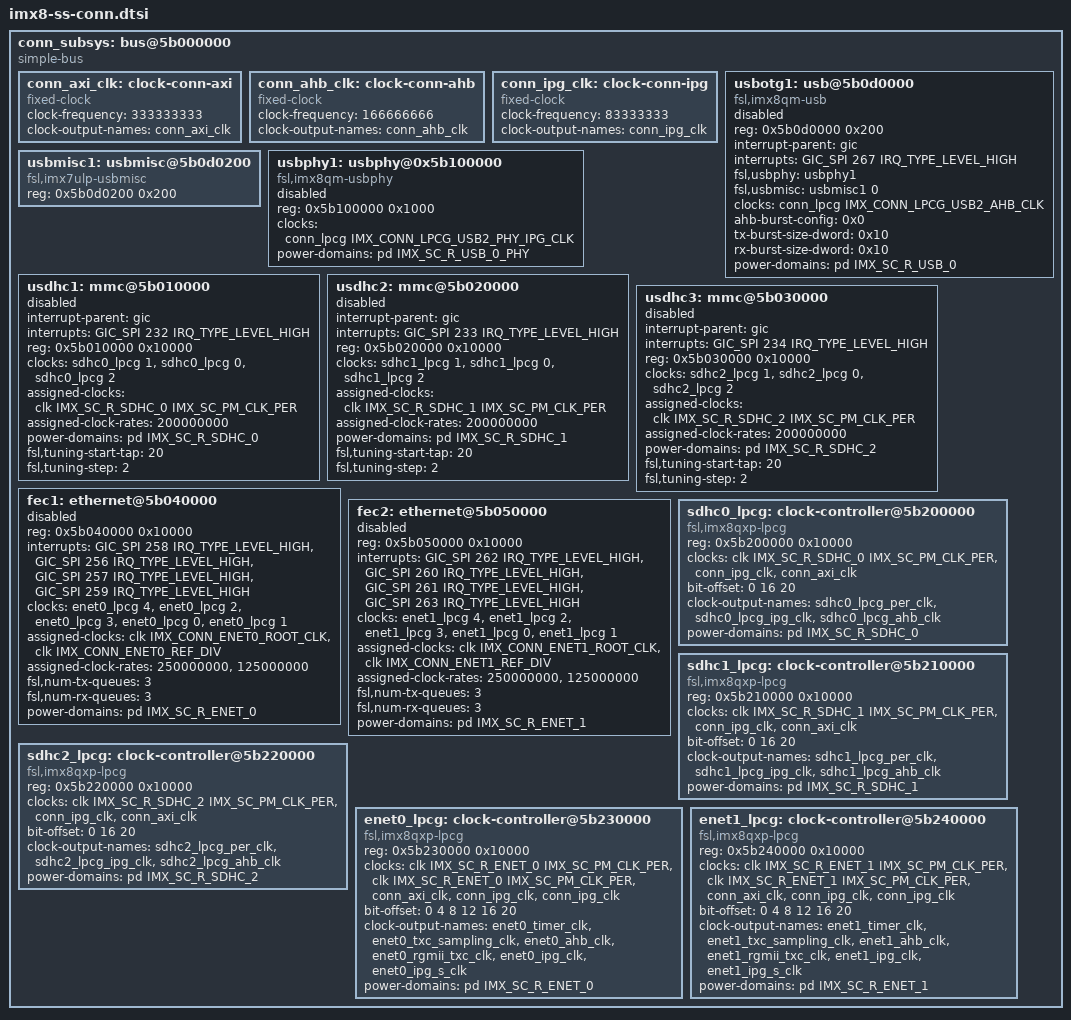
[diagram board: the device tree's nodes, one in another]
// SPDX-License-Identifier: GPL-2.0+
/*
 * Copyright 2018 NXP
 *	Dong Aisheng <aisheng.dong@nxp.com>
 */

#include <dt-bindings/firmware/imx/rsrc.h>

conn_subsys: bus@5b000000 {
	compatible = "simple-bus";
	#address-cells = <1>;
	#size-cells = <1>;
	ranges = <0x5b000000 0x0 0x5b000000 0x1000000>;

	conn_axi_clk: clock-conn-axi {
		compatible = "fixed-clock";
		#clock-cells = <0>;
		clock-frequency = <333333333>;
		clock-output-names = "conn_axi_clk";
	};

	conn_ahb_clk: clock-conn-ahb {
		compatible = "fixed-clock";
		#clock-cells = <0>;
		clock-frequency = <166666666>;
		clock-output-names = "conn_ahb_clk";
	};

	conn_ipg_clk: clock-conn-ipg {
		compatible = "fixed-clock";
		#clock-cells = <0>;
		clock-frequency = <83333333>;
		clock-output-names = "conn_ipg_clk";
	};

	usbotg1: usb@5b0d0000 {
		compatible = "fsl,imx8qm-usb", "fsl,imx7ulp-usb",
			"fsl,imx27-usb";
		reg = <0x5b0d0000 0x200>;
		interrupt-parent = <&gic>;
		interrupts = <GIC_SPI 267 IRQ_TYPE_LEVEL_HIGH>;
		fsl,usbphy = <&usbphy1>;
		fsl,usbmisc = <&usbmisc1 0>;
		clocks = <&conn_lpcg IMX_CONN_LPCG_USB2_AHB_CLK>;
		ahb-burst-config = <0x0>;
		tx-burst-size-dword = <0x10>;
		rx-burst-size-dword = <0x10>;
		power-domains = <&pd IMX_SC_R_USB_0>;
		status = "disabled";
	};

	usbmisc1: usbmisc@5b0d0200 {
		#index-cells = <1>;
		compatible = "fsl,imx7ulp-usbmisc", "fsl,imx6q-usbmisc";
		reg = <0x5b0d0200 0x200>;
	};

	usbphy1: usbphy@0x5b100000 {
		compatible = "fsl,imx8qm-usbphy", "fsl,imx7ulp-usbphy",
			"fsl,imx6ul-usbphy", "fsl,imx23-usbphy";
		reg = <0x5b100000 0x1000>;
		clocks = <&conn_lpcg IMX_CONN_LPCG_USB2_PHY_IPG_CLK>;
		power-domains = <&pd IMX_SC_R_USB_0_PHY>;
		status = "disabled";
	};

	usdhc1: mmc@5b010000 {
		interrupt-parent = <&gic>;
		interrupts = <GIC_SPI 232 IRQ_TYPE_LEVEL_HIGH>;
		reg = <0x5b010000 0x10000>;
		clocks = <&sdhc0_lpcg 1>,
			 <&sdhc0_lpcg 0>,
			 <&sdhc0_lpcg 2>;
		clock-names = "ipg", "per", "ahb";
		assigned-clocks = <&clk IMX_SC_R_SDHC_0 IMX_SC_PM_CLK_PER>;
		assigned-clock-rates = <200000000>;
		power-domains = <&pd IMX_SC_R_SDHC_0>;
		fsl,tuning-start-tap = <20>;
		fsl,tuning-step= <2>;
		status = "disabled";
	};

	usdhc2: mmc@5b020000 {
		interrupt-parent = <&gic>;
		interrupts = <GIC_SPI 233 IRQ_TYPE_LEVEL_HIGH>;
		reg = <0x5b020000 0x10000>;
		clocks = <&sdhc1_lpcg 1>,
			 <&sdhc1_lpcg 0>,
			 <&sdhc1_lpcg 2>;
		clock-names = "ipg", "per", "ahb";
		assigned-clocks = <&clk IMX_SC_R_SDHC_1 IMX_SC_PM_CLK_PER>;
		assigned-clock-rates = <200000000>;
		power-domains = <&pd IMX_SC_R_SDHC_1>;
		fsl,tuning-start-tap = <20>;
		fsl,tuning-step= <2>;
		status = "disabled";
	};

	usdhc3: mmc@5b030000 {
		interrupt-parent = <&gic>;
		interrupts = <GIC_SPI 234 IRQ_TYPE_LEVEL_HIGH>;
		reg = <0x5b030000 0x10000>;
		clocks = <&sdhc2_lpcg 1>,
			 <&sdhc2_lpcg 0>,
			 <&sdhc2_lpcg 2>;
		clock-names = "ipg", "per", "ahb";
		assigned-clocks = <&clk IMX_SC_R_SDHC_2 IMX_SC_PM_CLK_PER>;
		assigned-clock-rates = <200000000>;
		power-domains = <&pd IMX_SC_R_SDHC_2>;
		fsl,tuning-start-tap = <20>;
		fsl,tuning-step= <2>;
		status = "disabled";
	};

	fec1: ethernet@5b040000 {
		reg = <0x5b040000 0x10000>;
		interrupts = <GIC_SPI 258 IRQ_TYPE_LEVEL_HIGH>,
			     <GIC_SPI 256 IRQ_TYPE_LEVEL_HIGH>,
			     <GIC_SPI 257 IRQ_TYPE_LEVEL_HIGH>,
			     <GIC_SPI 259 IRQ_TYPE_LEVEL_HIGH>;
		clocks = <&enet0_lpcg 4>,
			 <&enet0_lpcg 2>,
			 <&enet0_lpcg 3>,
			 <&enet0_lpcg 0>,
			 <&enet0_lpcg 1>;
		clock-names = "ipg", "ahb", "enet_clk_ref", "ptp", "enet_2x_txclk";
		assigned-clocks = <&clk IMX_CONN_ENET0_ROOT_CLK>,
				  <&clk IMX_CONN_ENET0_REF_DIV>;
		assigned-clock-rates = <250000000>, <125000000>;
		fsl,num-tx-queues=<3>;
		fsl,num-rx-queues=<3>;
		power-domains = <&pd IMX_SC_R_ENET_0>;
		status = "disabled";
	};

	fec2: ethernet@5b050000 {
		reg = <0x5b050000 0x10000>;
		interrupts = <GIC_SPI 262 IRQ_TYPE_LEVEL_HIGH>,
				<GIC_SPI 260 IRQ_TYPE_LEVEL_HIGH>,
				<GIC_SPI 261 IRQ_TYPE_LEVEL_HIGH>,
				<GIC_SPI 263 IRQ_TYPE_LEVEL_HIGH>;
		clocks = <&enet1_lpcg 4>,
			 <&enet1_lpcg 2>,
			 <&enet1_lpcg 3>,
			 <&enet1_lpcg 0>,
			 <&enet1_lpcg 1>;
		clock-names = "ipg", "ahb", "enet_clk_ref", "ptp", "enet_2x_txclk";
		assigned-clocks = <&clk IMX_CONN_ENET1_ROOT_CLK>,
				  <&clk IMX_CONN_ENET1_REF_DIV>;
		assigned-clock-rates = <250000000>, <125000000>;
		fsl,num-tx-queues=<3>;
		fsl,num-rx-queues=<3>;
		power-domains = <&pd IMX_SC_R_ENET_1>;
		status = "disabled";
	};

	/* LPCG clocks */
	sdhc0_lpcg: clock-controller@5b200000 {
		compatible = "fsl,imx8qxp-lpcg";
		reg = <0x5b200000 0x10000>;
		#clock-cells = <1>;
		clocks = <&clk IMX_SC_R_SDHC_0 IMX_SC_PM_CLK_PER>,
			 <&conn_ipg_clk>, <&conn_axi_clk>;
		bit-offset = <0 16 20>;
		clock-output-names = "sdhc0_lpcg_per_clk",
				     "sdhc0_lpcg_ipg_clk",
				     "sdhc0_lpcg_ahb_clk";
		power-domains = <&pd IMX_SC_R_SDHC_0>;
	};

	sdhc1_lpcg: clock-controller@5b210000 {
		compatible = "fsl,imx8qxp-lpcg";
		reg = <0x5b210000 0x10000>;
		#clock-cells = <1>;
		clocks = <&clk IMX_SC_R_SDHC_1 IMX_SC_PM_CLK_PER>,
			 <&conn_ipg_clk>, <&conn_axi_clk>;
		bit-offset = <0 16 20>;
		clock-output-names = "sdhc1_lpcg_per_clk",
				     "sdhc1_lpcg_ipg_clk",
				     "sdhc1_lpcg_ahb_clk";
		power-domains = <&pd IMX_SC_R_SDHC_1>;
	};

	sdhc2_lpcg: clock-controller@5b220000 {
		compatible = "fsl,imx8qxp-lpcg";
		reg = <0x5b220000 0x10000>;
		#clock-cells = <1>;
		clocks = <&clk IMX_SC_R_SDHC_2 IMX_SC_PM_CLK_PER>,
			 <&conn_ipg_clk>, <&conn_axi_clk>;
		bit-offset = <0 16 20>;
		clock-output-names = "sdhc2_lpcg_per_clk",
				     "sdhc2_lpcg_ipg_clk",
				     "sdhc2_lpcg_ahb_clk";
		power-domains = <&pd IMX_SC_R_SDHC_2>;
	};

	enet0_lpcg: clock-controller@5b230000 {
		compatible = "fsl,imx8qxp-lpcg";
		reg = <0x5b230000 0x10000>;
		#clock-cells = <1>;
		clocks = <&clk IMX_SC_R_ENET_0 IMX_SC_PM_CLK_PER>,
			 <&clk IMX_SC_R_ENET_0 IMX_SC_PM_CLK_PER>,
			 <&conn_axi_clk>, <&conn_ipg_clk>, <&conn_ipg_clk>;
		bit-offset = <0 4 8 12 16 20>;
		clock-output-names = "enet0_timer_clk",
				     "enet0_txc_sampling_clk",
				     "enet0_ahb_clk",
				     "enet0_rgmii_txc_clk",
				     "enet0_ipg_clk",
				     "enet0_ipg_s_clk";
		power-domains = <&pd IMX_SC_R_ENET_0>;
	};

	enet1_lpcg: clock-controller@5b240000 {
		compatible = "fsl,imx8qxp-lpcg";
		reg = <0x5b240000 0x10000>;
		#clock-cells = <1>;
		clocks = <&clk IMX_SC_R_ENET_1 IMX_SC_PM_CLK_PER>,
			 <&clk IMX_SC_R_ENET_1 IMX_SC_PM_CLK_PER>,
			 <&conn_axi_clk>, <&conn_ipg_clk>, <&conn_ipg_clk>;
		bit-offset = <0 4 8 12 16 20>;
		clock-output-names = "enet1_timer_clk",
				     "enet1_txc_sampling_clk",
				     "enet1_ahb_clk",
				     "enet1_rgmii_txc_clk",
				     "enet1_ipg_clk",
				     "enet1_ipg_s_clk";
		power-domains = <&pd IMX_SC_R_ENET_1>;
	};
};
